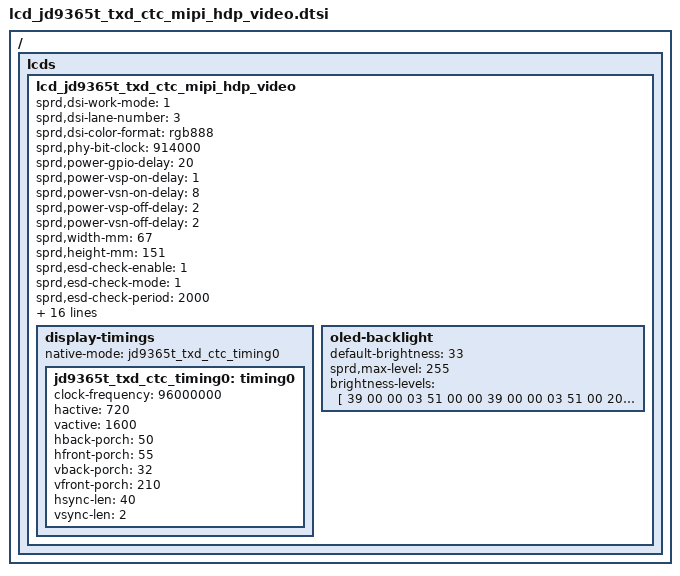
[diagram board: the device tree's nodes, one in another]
/*
 * jd9365t  LCD config dtsi file for spreadtrum
 *
 * Copyright (C) 2018, Spreadtrum Communications Inc.
 *
 * SPDX-License-Identifier: (GPL-2.0+ OR MIT)
 */

/ {
    fragment {
        target-path = "/";
        __overlay__ {
            lcds {
                lcd_jd9365t_txd_ctc_mipi_hdp_video: lcd_jd9365t_txd_ctc_mipi_hdp_video {
                    sprd,dsi-work-mode = <1>; /* video burst mode*/
                    sprd,dsi-lane-number = <3>;
                    sprd,dsi-color-format = "rgb888";

                    sprd,phy-bit-clock = <914000>; /* kbps */
                    //sprd,phy-escape-clock = <20000>;/* kHz */
                    //sprd,dpi-clk-div = <1>;
                    sprd,power-gpio-delay = <20>;/* ms */
                    sprd,power-vsp-on-delay = <1>;
                    sprd,power-vsn-on-delay = <8>;
                    sprd,power-vsp-off-delay = <2>;
                    sprd,power-vsn-off-delay = <2>;

                    sprd,width-mm = <67>;
                    sprd,height-mm = <151>;

                    sprd,esd-check-enable = <1>;
                    sprd,esd-check-mode = <1>;
                    sprd,esd-check-period = <2000>;

                    sprd,reset-on-sequence = <1 5>, <0 10>, <1 10>;
                    sprd,reset-off-sequence = <0 5>;

                    sprd,ddi-need-tp-reset = <1>;
                    sprd,ddi-tp-reset-gpio = <209>;

                    sprd,reset-force-pull-low = <1>;
                    sprd,reset-delay-vspn-ms = <5>;

                    sprd,deep-sleep-in = <1>;

                    sprd,use-dcs-write;
                    sprd,initial-command = [
                        39 00 00 04 df 93 83 16
                        39 00 00 02 de 00
                        39 00 00 13 b3 10 80 85 00 65 1e 00 00 00 00 64 64 3c 3c 33 11 5a 5a
                        39 00 00 06 b2 01 23 60 88 24
                        39 00 00 04 b6 0c 99 ae
                        39 00 00 04 b9 3c 33 35
                        39 00 00 08 bb 0c 31 43 64 3c 20 20
                        39 00 00 05 bc 2e 40 43 00
                        39 00 00 03 bd 00 b1
                        39 00 00 06 c0 00 d5 10 d5 10
                        39 00 00 2b cb 5e 54 4c 3e 32 2e 1f 24 0e 27 26 24 40 2b 31 23 20 15 08 03 02 5e 54 4c 3e 32 2e 1f 24 0e 27 26 24 40 2b 31 23 20 15 08 03 02
                        39 00 00 02 cc 32
                        39 00 00 03 cd 10 10
                        39 00 00 05 bf 5a 3c 33 c3
                        39 00 00 0e c3 13 00 06 16 99 00 9e 08 16 04 18 08 16
                        39 00 00 0b c5 30 20 87 00 00 00 00 38 00 11
                        39 00 00 05 c6 00 b6 d2 14
                        39 00 00 13 ce 01 3c 00 00 00 3c 00 3c 3f 3f 00 3c 3c 3c 3c 00 3c 3c
                        39 00 00 11 cf 00 00 00 00 00 00 c0 c0 c0 c0 c0 c0 c0 c0 c0 c0
                        39 00 00 1e d0 00 1f 1f 1f 1f 1f 1f 15 15 16 1f 05 07 09 0b 1f 01 03 1f 1f 1f 1f 1f 00 00 00 00 00 00
                        39 00 00 1e d1 00 1f 1f 1f 1f 1f 1f 15 15 16 1f 04 06 08 0a 1f 00 02 1f 1f 1f 1f 1f 00 00 00 00 00 00
                        39 00 00 1e d2 00 1f 1f 1f 1f 15 1f 1f 15 16 1f 0a 08 06 04 1f 02 00 1f 1f 1f 1f 1f 00 00 00 03 00 00
                        39 00 00 1e d3 00 1f 1f 1f 1f 15 1f 1f 15 16 1f 0b 09 07 05 1f 03 01 1f 1f 1f 1f 1f 00 00 00 03 00 00
                        39 00 00 3f d4 30 00 00 07 00 09 00 00 00 00 00 06 06 00 10 26 54 00 04 03 03 00 01 00 04 01 01 11 60 03 00 05 01 01 00 00 06 04 07 06 55 06 53 00 00 00 00 00 00 00 00 00 00 00 00 00 00 00 00 81 03 d4
                        39 00 00 1c d5 03 10 03 00 01 00 00 00 00 43 00 00 00 07 32 5a 00 48 77 00 02 1e 02 73 00 0e 08
                        39 00 00 14 d7 00 7c 7c 7c 7c 7c 7c 7c 7c 7c 7c 7c 7c 7c 7c 7c 7c 7c 7c
                        39 00 00 02 de 01
                        39 00 00 02 b5 6f
                        39 00 00 03 c5 22 12
                        39 00 00 08 c6 3f 0c 00 00 01 80 60
                        39 00 00 02 de 02
                        39 00 00 06 b3 20 a0 ea 5f 4b
                        39 00 00 09 b7 44 00 88 00 03 00 6e 10
                        39 00 00 02 bd 14
                        39 00 00 09 c1 00 40 20 00 14 14 14 14
                        39 00 00 08 c2 42 70 01 01 e0 73 f8
                        39 00 00 07 c3 20 fb 00 a0 20 62
                        39 00 00 02 c6 05
                        39 00 00 0b e5 00 e6 e5 02 27 42 27 42 09 00
                        39 00 00 04 e6 10 20 a9
                        39 00 00 04 ec 01 7f 22
                        39 00 00 02 de 03
                        39 00 00 02 d1 00
                        39 00 00 02 de 00
                        39 00 00 02 35 00
                        39 00 00 03 51 00 00
                        39 00 00 02 53 2C
                        FF 00 00 01 00
                        05 96 00 02 11 00
                        05 14 00 02 29 00
                    ];

                    sprd,sleep-in-command = [
                        05 02 00 01 00
                        39 38 00 01 28
                        39 80 00 01 10
                    ];

                    sprd,sleep-out-command = [
                        39 78 00 01 11
                        39 32 00 01 29
                    ];

                    sprd,deep-sleep-in-command = [
                        05 02 00 01 00
                        39 38 00 01 28
                        39 80 00 01 10
                    ];

                    display-timings {
                        native-mode = <&jd9365t_txd_ctc_timing0>;

                        jd9365t_txd_ctc_timing0: timing0 {
                            clock-frequency = <96000000>;
                            hactive = <720>;
                            vactive = <1600>;
                            hback-porch = <50>;
                            hfront-porch = <55>;
                            vback-porch = <32>;
                            vfront-porch = <210>;
                            hsync-len = <40>;
                            vsync-len = <2>;
                        };
                    };

                    oled-backlight {
                        default-brightness = <33>;
                        sprd,max-level = <255>;
                        brightness-levels = [
                            39 00 00 03 51 00 00
                            39 00 00 03 51 00 20
                            39 00 00 03 51 00 30
                            39 00 00 03 51 00 40
                            39 00 00 03 51 00 50
                            39 00 00 03 51 00 60
                            39 00 00 03 51 00 70
                            39 00 00 03 51 00 80
                            39 00 00 03 51 00 90
                            39 00 00 03 51 00 A0
                            39 00 00 03 51 00 B0
                            39 00 00 03 51 00 C0
                            39 00 00 03 51 00 D0
                            39 00 00 03 51 00 E0
                            39 00 00 03 51 00 F0
                            39 00 00 03 51 01 00
                            39 00 00 03 51 01 11
                            39 00 00 03 51 01 21
                            39 00 00 03 51 01 31
                            39 00 00 03 51 01 41
                            39 00 00 03 51 01 51
                            39 00 00 03 51 01 61
                            39 00 00 03 51 01 71
                            39 00 00 03 51 01 81
                            39 00 00 03 51 01 91
                            39 00 00 03 51 01 A1
                            39 00 00 03 51 01 B1
                            39 00 00 03 51 01 C1
                            39 00 00 03 51 01 D1
                            39 00 00 03 51 01 E1
                            39 00 00 03 51 01 F1
                            39 00 00 03 51 02 01
                            39 00 00 03 51 02 11
                            39 00 00 03 51 02 22
                            39 00 00 03 51 02 32
                            39 00 00 03 51 02 42
                            39 00 00 03 51 02 52
                            39 00 00 03 51 02 62
                            39 00 00 03 51 02 72
                            39 00 00 03 51 02 82
                            39 00 00 03 51 02 92
                            39 00 00 03 51 02 A2
                            39 00 00 03 51 02 B2
                            39 00 00 03 51 02 C2
                            39 00 00 03 51 02 D2
                            39 00 00 03 51 02 E2
                            39 00 00 03 51 02 F2
                            39 00 00 03 51 03 02
                            39 00 00 03 51 03 12
                            39 00 00 03 51 03 22
                            39 00 00 03 51 03 32
                            39 00 00 03 51 03 43
                            39 00 00 03 51 03 53
                            39 00 00 03 51 03 63
                            39 00 00 03 51 03 73
                            39 00 00 03 51 03 83
                            39 00 00 03 51 03 93
                            39 00 00 03 51 03 A3
                            39 00 00 03 51 03 B3
                            39 00 00 03 51 03 C3
                            39 00 00 03 51 03 D3
                            39 00 00 03 51 03 E3
                            39 00 00 03 51 03 F3
                            39 00 00 03 51 04 03
                            39 00 00 03 51 04 13
                            39 00 00 03 51 04 23
                            39 00 00 03 51 04 33
                            39 00 00 03 51 04 43
                            39 00 00 03 51 04 54
                            39 00 00 03 51 04 64
                            39 00 00 03 51 04 74
                            39 00 00 03 51 04 84
                            39 00 00 03 51 04 94
                            39 00 00 03 51 04 A4
                            39 00 00 03 51 04 B4
                            39 00 00 03 51 04 C4
                            39 00 00 03 51 04 D4
                            39 00 00 03 51 04 E4
                            39 00 00 03 51 04 F4
                            39 00 00 03 51 05 04
                            39 00 00 03 51 05 14
                            39 00 00 03 51 05 24
                            39 00 00 03 51 05 34
                            39 00 00 03 51 05 44
                            39 00 00 03 51 05 54
                            39 00 00 03 51 05 65
                            39 00 00 03 51 05 75
                            39 00 00 03 51 05 85
                            39 00 00 03 51 05 95
                            39 00 00 03 51 05 A5
                            39 00 00 03 51 05 B5
                            39 00 00 03 51 05 C5
                            39 00 00 03 51 05 D5
                            39 00 00 03 51 05 E5
                            39 00 00 03 51 05 F5
                            39 00 00 03 51 06 05
                            39 00 00 03 51 06 15
                            39 00 00 03 51 06 25
                            39 00 00 03 51 06 35
                            39 00 00 03 51 06 45
                            39 00 00 03 51 06 55
                            39 00 00 03 51 06 65
                            39 00 00 03 51 06 76
                            39 00 00 03 51 06 86
                            39 00 00 03 51 06 96
                            39 00 00 03 51 06 A6
                            39 00 00 03 51 06 B6
                            39 00 00 03 51 06 C6
                            39 00 00 03 51 06 D6
                            39 00 00 03 51 06 E6
                            39 00 00 03 51 06 F6
                            39 00 00 03 51 07 06
                            39 00 00 03 51 07 16
                            39 00 00 03 51 07 26
                            39 00 00 03 51 07 36
                            39 00 00 03 51 07 46
                            39 00 00 03 51 07 56
                            39 00 00 03 51 07 66
                            39 00 00 03 51 07 76
                            39 00 00 03 51 07 87
                            39 00 00 03 51 07 97
                            39 00 00 03 51 07 A7
                            39 00 00 03 51 07 B7
                            39 00 00 03 51 07 C7
                            39 00 00 03 51 07 D7
                            39 00 00 03 51 07 E7
                            39 00 00 03 51 07 F7
                            39 00 00 03 51 08 07
                            39 00 00 03 51 08 17
                            39 00 00 03 51 08 27
                            39 00 00 03 51 08 37
                            39 00 00 03 51 08 47
                            39 00 00 03 51 08 57
                            39 00 00 03 51 08 67
                            39 00 00 03 51 08 77
                            39 00 00 03 51 08 87
                            39 00 00 03 51 08 98
                            39 00 00 03 51 08 A8
                            39 00 00 03 51 08 B8
                            39 00 00 03 51 08 C8
                            39 00 00 03 51 08 D8
                            39 00 00 03 51 08 E8
                            39 00 00 03 51 08 F8
                            39 00 00 03 51 09 08
                            39 00 00 03 51 09 18
                            39 00 00 03 51 09 28
                            39 00 00 03 51 09 38
                            39 00 00 03 51 09 48
                            39 00 00 03 51 09 58
                            39 00 00 03 51 09 68
                            39 00 00 03 51 09 78
                            39 00 00 03 51 09 88
                            39 00 00 03 51 09 98
                            39 00 00 03 51 09 A9
                            39 00 00 03 51 09 B9
                            39 00 00 03 51 09 C9
                            39 00 00 03 51 09 D9
                            39 00 00 03 51 09 E9
                            39 00 00 03 51 09 F9
                            39 00 00 03 51 0A 09
                            39 00 00 03 51 0A 19
                            39 00 00 03 51 0A 29
                            39 00 00 03 51 0A 39
                            39 00 00 03 51 0A 49
                            39 00 00 03 51 0A 59
                            39 00 00 03 51 0A 69
                            39 00 00 03 51 0A 79
                            39 00 00 03 51 0A 89
                            39 00 00 03 51 0A 99
                            39 00 00 03 51 0A A9
                            39 00 00 03 51 0A BA
                            39 00 00 03 51 0A CA
                            39 00 00 03 51 0A DA
                            39 00 00 03 51 0A EA
                            39 00 00 03 51 0A FA
                            39 00 00 03 51 0B 0A
                            39 00 00 03 51 0B 1A
                            39 00 00 03 51 0B 2A
                            39 00 00 03 51 0B 3A
                            39 00 00 03 51 0B 4A
                            39 00 00 03 51 0B 5A
                            39 00 00 03 51 0B 6A
                            39 00 00 03 51 0B 7A
                            39 00 00 03 51 0B 8A
                            39 00 00 03 51 0B 9A
                            39 00 00 03 51 0B AA
                            39 00 00 03 51 0B BA
                            39 00 00 03 51 0B CB
                            39 00 00 03 51 0B DB
                            39 00 00 03 51 0B EB
                            39 00 00 03 51 0B FB
                            39 00 00 03 51 0C 0B
                            39 00 00 03 51 0C 1B
                            39 00 00 03 51 0C 2B
                            39 00 00 03 51 0C 3B
                            39 00 00 03 51 0C 4B
                            39 00 00 03 51 0C 5B
                            39 00 00 03 51 0C 6B
                            39 00 00 03 51 0C 7B
                            39 00 00 03 51 0C 8B
                            39 00 00 03 51 0C 9B
                            39 00 00 03 51 0C AB
                            39 00 00 03 51 0C BB
                            39 00 00 03 51 0C CB
                            39 00 00 03 51 0C DC
                            39 00 00 03 51 0C EC
                            39 00 00 03 51 0C FC
                            39 00 00 03 51 0D 0C
                            39 00 00 03 51 0D 1C
                            39 00 00 03 51 0D 2C
                            39 00 00 03 51 0D 3C
                            39 00 00 03 51 0D 4C
                            39 00 00 03 51 0D 5C
                            39 00 00 03 51 0D 6C
                            39 00 00 03 51 0D 7C
                            39 00 00 03 51 0D 8C
                            39 00 00 03 51 0D 9C
                            39 00 00 03 51 0D AC
                            39 00 00 03 51 0D BC
                            39 00 00 03 51 0D CC
                            39 00 00 03 51 0D DC
                            39 00 00 03 51 0D ED
                            39 00 00 03 51 0D FD
                            39 00 00 03 51 0E 0D
                            39 00 00 03 51 0E 1D
                            39 00 00 03 51 0E 2D
                            39 00 00 03 51 0E 3D
                            39 00 00 03 51 0E 4D
                            39 00 00 03 51 0E 5D
                            39 00 00 03 51 0E 6D
                            39 00 00 03 51 0E 7D
                            39 00 00 03 51 0E 8D
                            39 00 00 03 51 0E 9D
                            39 00 00 03 51 0E AD
                            39 00 00 03 51 0E BD
                            39 00 00 03 51 0E CD
                            39 00 00 03 51 0E DD
                            39 00 00 03 51 0E ED
                            39 00 00 03 51 0E FE
                            39 00 00 03 51 0F 0E
                            39 00 00 03 51 0F 1E
                            39 00 00 03 51 0F 2E
                            39 00 00 03 51 0F 3E
                            39 00 00 03 51 0F 4E
                            39 00 00 03 51 0F 5E
                            39 00 00 03 51 0F 6E
                            39 00 00 03 51 0F 7E
                            39 00 00 03 51 0F 8E
                            39 00 00 03 51 0F 9E
                            39 00 00 03 51 0F AE
                            39 00 00 03 51 0F BE
                            39 00 00 03 51 0F CE
                            39 00 00 03 51 0F DE
                            39 00 00 03 51 0F EE
                            39 00 00 03 51 0F FE
                            39 00 00 03 51 0F FE
                        ];
                    };
                };
            };
        };
    };
};
